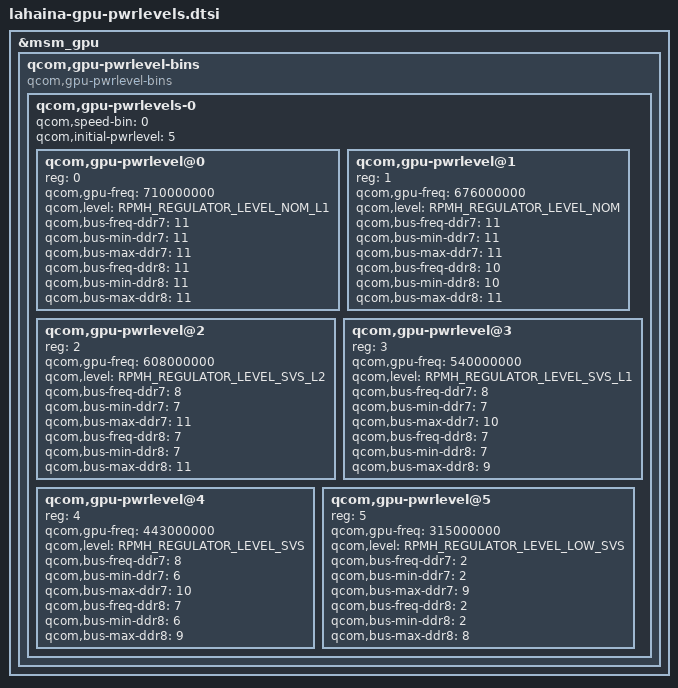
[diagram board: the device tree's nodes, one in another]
// SPDX-License-Identifier: BSD-3-Clause
/*
 * Copyright (c) Qualcomm Technologies, Inc. and/or its subsidiaries.
 */

&msm_gpu {
	qcom,gpu-pwrlevel-bins {
		#address-cells = <1>;
		#size-cells = <0>;

		compatible = "qcom,gpu-pwrlevel-bins";

		qcom,gpu-pwrlevels-0 {
			#address-cells = <1>;
			#size-cells = <0>;

			qcom,speed-bin = <0>;
			qcom,initial-pwrlevel = <5>;

			qcom,gpu-pwrlevel@0 {
				reg = <0>;
				qcom,gpu-freq = <710000000>;
				qcom,level = <RPMH_REGULATOR_LEVEL_NOM_L1>;

				qcom,bus-freq-ddr7 = <11>;
				qcom,bus-min-ddr7 = <11>;
				qcom,bus-max-ddr7 = <11>;

				qcom,bus-freq-ddr8 = <11>;
				qcom,bus-min-ddr8 = <11>;
				qcom,bus-max-ddr8 = <11>;
			};

			qcom,gpu-pwrlevel@1 {
				reg = <1>;
				qcom,gpu-freq = <676000000>;
				qcom,level = <RPMH_REGULATOR_LEVEL_NOM>;

				qcom,bus-freq-ddr7 = <11>;
				qcom,bus-min-ddr7 = <11>;
				qcom,bus-max-ddr7 = <11>;

				qcom,bus-freq-ddr8 = <10>;
				qcom,bus-min-ddr8 = <10>;
				qcom,bus-max-ddr8 = <11>;
			};

			qcom,gpu-pwrlevel@2 {
				reg = <2>;
				qcom,gpu-freq = <608000000>;
				qcom,level = <RPMH_REGULATOR_LEVEL_SVS_L2>;

				qcom,bus-freq-ddr7 = <8>;
				qcom,bus-min-ddr7 = <7>;
				qcom,bus-max-ddr7 = <11>;

				qcom,bus-freq-ddr8 = <7>;
				qcom,bus-min-ddr8 = <7>;
				qcom,bus-max-ddr8 = <11>;
			};

			qcom,gpu-pwrlevel@3 {
				reg = <3>;
				qcom,gpu-freq = <540000000>;
				qcom,level = <RPMH_REGULATOR_LEVEL_SVS_L1>;

				qcom,bus-freq-ddr7 = <8>;
				qcom,bus-min-ddr7 = <7>;
				qcom,bus-max-ddr7 = <10>;

				qcom,bus-freq-ddr8 = <7>;
				qcom,bus-min-ddr8 = <7>;
				qcom,bus-max-ddr8 = <9>;
			};

			qcom,gpu-pwrlevel@4 {
				reg = <4>;
				qcom,gpu-freq = <443000000>;
				qcom,level = <RPMH_REGULATOR_LEVEL_SVS>;

				qcom,bus-freq-ddr7 = <8>;
				qcom,bus-min-ddr7 = <6>;
				qcom,bus-max-ddr7 = <10>;

				qcom,bus-freq-ddr8 = <7>;
				qcom,bus-min-ddr8 = <6>;
				qcom,bus-max-ddr8 = <9>;
			};

			qcom,gpu-pwrlevel@5 {
				reg = <5>;
				qcom,gpu-freq = <315000000>;
				qcom,level = <RPMH_REGULATOR_LEVEL_LOW_SVS>;

				qcom,bus-freq-ddr7 = <2>;
				qcom,bus-min-ddr7 = <2>;
				qcom,bus-max-ddr7 = <9>;

				qcom,bus-freq-ddr8 = <2>;
				qcom,bus-min-ddr8 = <2>;
				qcom,bus-max-ddr8 = <8>;
			};
		};
	};
};
